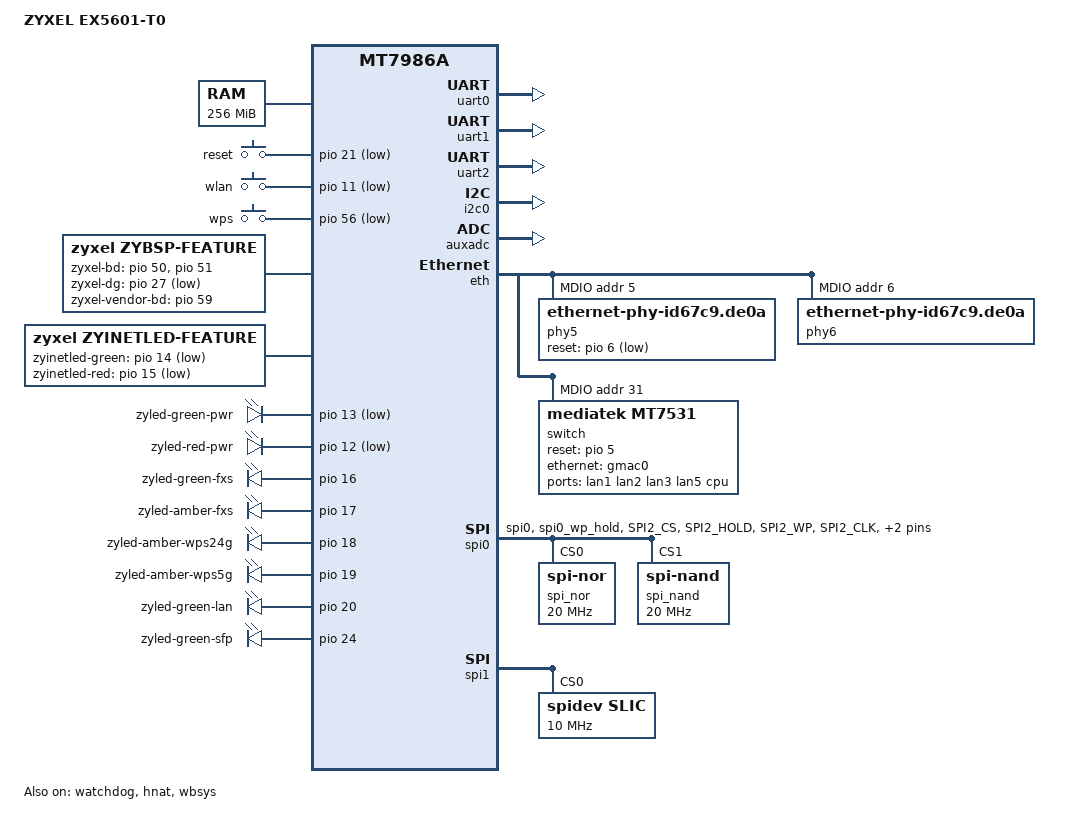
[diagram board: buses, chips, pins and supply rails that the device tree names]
/dts-v1/;
#include "mt7986a.dtsi"
#include "mt7986a-pinctrl.dtsi"
#include "mt7986-spim-nand-512M-256kB-partition.dtsi"
#include <dt-bindings/input/input.h>
#include <dt-bindings/gpio/gpio.h>
/ {
	model = "ZYXEL EX5601-T0";
	compatible = "mediatek,mt7986a-2500wan-spim-snand-ex5601-t0";
	chosen {
		bootargs = "console=ttyS0,115200n1 loglevel=8  \
				earlycon=uart8250,mmio32,0x11002000";
	};

	memory {
		reg = <0 0x40000000 0 0x10000000>;
	};

	sound_si3218x {
		compatible = "mediatek,mt79xx-si3218x-machine";
		mediatek,platform = <&afe>;
		/* mediatek,ext-codec = <&proslic_spi>; */
		mediatek,ext-codec = <&dummy_codec>;
		status = "okay";
	};

	dummy_codec:dummy_codec {
			compatible = "d2,slic-dummy-codec";
	};

	gpio-keys {
		compatible = "gpio-keys";
		poll-interval = <20>;

		reset-button {
			label = "reset";
			gpios = <&pio 21 GPIO_ACTIVE_LOW>;
			linux,code = <KEY_RESTART>;
		};
		wlan-button {
			label = "wlan";
			gpios = <&pio 11 GPIO_ACTIVE_LOW>;
			linux,code = <KEY_WLAN>;
		};
		wps-button {
			label = "wps";
			gpios = <&pio 56 GPIO_ACTIVE_LOW>;
			linux,code = <KEY_WPS_BUTTON>;
		};
	};

	zybsp {
		compatible = "zyxel,zybsp-feature";
		zyxel-bd-gpios = <&pio 50 GPIO_ACTIVE_HIGH>,<&pio 51 GPIO_ACTIVE_HIGH>;
		zyxel-dg-gpios = <&pio 27 GPIO_ACTIVE_LOW>;
		zyxel-vendor-bd-gpios = <&pio 59 GPIO_ACTIVE_HIGH>;
	};

	zyinetled {
		compatible = "zyxel,zyinetled-feature";
		zyinetled-green-gpios = <&pio 14 GPIO_ACTIVE_LOW>;
		zyinetled-red-gpios = <&pio 15 GPIO_ACTIVE_LOW>;
	};

	zyleds {
		compatible = "gpio-leds";

		led_green_pwr {
			label = "zyled-green-pwr";
			gpios = <&pio 13 GPIO_ACTIVE_LOW>;
			linux,default-trigger = "timer"; /* Default blinking */
			led-pattern = <125 125>; /* Fast blink is 4 HZ */
		};

		led_red_pwr {
			label = "zyled-red-pwr";
			gpios = <&pio 12 GPIO_ACTIVE_LOW>;
			default-state = "off";
		};

		led_green_fxs {
			label = "zyled-green-fxs";
			gpios = <&pio 16 GPIO_ACTIVE_HIGH>;
			default-state = "off";
		};

		led_amber_fxs {
			label = "zyled-amber-fxs";
			gpios = <&pio 17 GPIO_ACTIVE_HIGH>;
			default-state = "off";
		};

		led_amber_wps24g {
			label = "zyled-amber-wps24g";
			gpios = <&pio 18 GPIO_ACTIVE_HIGH>;
			default-state = "off";
		};

		led_amber_wps5g {
			label = "zyled-amber-wps5g";
			gpios = <&pio 19 GPIO_ACTIVE_HIGH>;
			default-state = "off";
		};

		led_green_lan {
			label = "zyled-green-lan";
			gpios = <&pio 20 GPIO_ACTIVE_HIGH>;
			default-state = "off";
		};

		led_green_sfp {
			label = "zyled-green-sfp";
			gpios = <&pio 24 GPIO_ACTIVE_HIGH>;
			default-state = "off";
		};

	};

};

&pwm {
	pinctrl-names = "default";
	pinctrl-0 = <&pwm0_pin &pwm1_pin_g1>;
	status = "disabled";
};

&uart0 {
	status = "okay";
};

&uart1 {
	pinctrl-names = "default";
	pinctrl-0 = <&uart1_pins>;
	status = "okay";
};

&uart2 {
	pinctrl-names = "default";
	pinctrl-0 = <&uart2_pins>;
	status = "okay";
};

&i2c0 {
	pinctrl-names = "default";
	pinctrl-0 = <&i2c_pins>;
	status = "okay";
};

&auxadc {
	status = "okay";
};

&watchdog {
	status = "okay";
};

&eth {
	status = "okay";

	gmac0: mac@0 {
		compatible = "mediatek,eth-mac";
		reg = <0>;
		phy-mode = "2500base-x";

		fixed-link {
			speed = <2500>;
			full-duplex;
			pause;
		};
	};

	gmac1: mac@1 {
		compatible = "mediatek,eth-mac";
		reg = <1>;
		phy-mode = "2500base-x";

		fixed-link {
			speed = <2500>;
			full-duplex;
			pause;
		};
	};

	mdio: mdio-bus {
		#address-cells = <1>;
		#size-cells = <0>;

		phy5: phy@5 {
			compatible = "ethernet-phy-id67c9.de0a";
			reg = <5>;
			reset-gpios = <&pio 6 1>;
			reset-assert-us = <50000>;
			reset-deassert-us = <20000>;
			phy-mode = "2500base-x";
			maxlinear,led-reg = <1008 0 0 0>; /* enable led0 for all link/act, and disable led1~3 */
			ifname = "lan5";
		};

		phy6: phy@6 {
			compatible = "ethernet-phy-id67c9.de0a";
			reg = <6>;
			phy-mode = "2500base-x";
			maxlinear,led-reg = <240 0 0 0>; /* enable led0 and no pulsing with TX, RX, and disable led1~3 */
			ifname = "eth1";
		};

		switch@0 {
			compatible = "mediatek,mt7531";
			reg = <31>;
			reset-gpios = <&pio 5 0>;

			ports {
				#address-cells = <1>;
				#size-cells = <0>;

				port@1 {
					reg = <1>;
					label = "lan1";
				};

				port@2 {
					reg = <2>;
					label = "lan2";
				};

				port@3 {
					reg = <3>;
					label = "lan3";
				};

				port@5 {
					reg = <5>;
					label = "lan5";
					phy-mode = "2500base-x";

					fixed-link {
						speed = <2500>;
						full-duplex;
						pause;
					};
				};

				port@6 {
					reg = <6>;
					label = "cpu";
					ethernet = <&gmac0>;
					phy-mode = "2500base-x";

					fixed-link {
						speed = <2500>;
						full-duplex;
						pause;
					};
				};
			};
		};
	};
};

&xhci {
	mtk,enable-gpios = <&pio 8 1>;
	mtk,oc-gpios = <&pio 7 1>;
};

&hnat {
	mtketh-wan = "eth1";
	mtketh-lan = "lan";
	mtketh-max-gmac = <2>;
	status = "okay";
};

&spi0 {
	pinctrl-names = "default";
	pinctrl-0 = <&spi_flash_pins>;
	cs-gpios = <0>, <0>;
	status = "okay";

	spi_nor@0 {
		#address-cells = <1>;
		#size-cells = <1>;
		compatible = "jedec,spi-nor";
		reg = <0>;
		spi-max-frequency = <20000000>;
		spi-tx-buswidth = <4>;
		spi-rx-buswidth = <4>;
	};

	spi_nand: spi_nand@1 {
		#address-cells = <1>;
		#size-cells = <1>;
		compatible = "spi-nand";
		reg = <1>;
		spi-max-frequency = <20000000>;
		spi-tx-buswidth = <4>;
		spi-rx-buswidth = <4>;
	};
};

&spi1 {
	pinctrl-names = "default";
	pinctrl-0 = <&spic_pins_g2>;
	status = "okay";

	/*
	 * proslic_spi: proslic_spi@0 {
	 *	compatible = "silabs,proslic_spi";
	 *	reg = <0>;
	 *	spi-max-frequency = <10000000>;
	 *	spi-cpha = <1>;
	 *	spi-cpol = <1>;
	 *	channel_count = <1>;
	 *	debug_level = <4>;       // 1 = TRC, 2 = DBG, 4 = ERR //
	 *	reset_gpio = <&pio 25 0>;
	 *	ig,enable-spi = <1>;     // 1: Enable, 0: Disable //
	 * };
	 */

    spidev@0 {
        compatible = "spidev,slic";
        spi-max-frequency = <10000000>;
        reg = <0>;

	};

};

&pcie0 {
	pinctrl-names = "default";
	pinctrl-0 = <&pcie0_pins>;
	status = "disabled";
};

&wbsys {
	mediatek,mtd-eeprom = <&factory 0x0000>;
	status = "okay";
	pinctrl-names = "default", "dbdc";
	pinctrl-0 = <&wf_2g_5g_pins>;
	pinctrl-1 = <&wf_dbdc_pins>;
};

&pio {
	spi_flash_pins: spi-flash-pins-33-to-38 {
		mux {
			function = "flash";
			groups = "spi0", "spi0_wp_hold";
		};
		conf-pu {
			pins = "SPI2_CS", "SPI2_HOLD", "SPI2_WP";
			drive-strength = <MTK_DRIVE_8mA>;
			mediatek,pull-up-adv = <0>;	/* bias-disable */
		};
		conf-pd {
			pins = "SPI2_CLK", "SPI2_MOSI", "SPI2_MISO";
			drive-strength = <MTK_DRIVE_8mA>;
			mediatek,pull-down-adv = <0>;	/* bias-disable */
		};
	};

	wf_2g_5g_pins: wf_2g_5g-pins {
		mux {
			function = "wifi";
			groups = "wf_2g", "wf_5g";
		};
		conf {
			pins = "WF0_HB1", "WF0_HB2", "WF0_HB3", "WF0_HB4",
			       "WF0_HB0", "WF0_HB0_B", "WF0_HB5", "WF0_HB6",
			       "WF0_HB7", "WF0_HB8", "WF0_HB9", "WF0_HB10",
			       "WF0_TOP_CLK", "WF0_TOP_DATA", "WF1_HB1",
			       "WF1_HB2", "WF1_HB3", "WF1_HB4", "WF1_HB0",
			       "WF1_HB5", "WF1_HB6", "WF1_HB7", "WF1_HB8",
			       "WF1_TOP_CLK", "WF1_TOP_DATA";
			drive-strength = <MTK_DRIVE_4mA>;
		};
	};

	wf_dbdc_pins: wf_dbdc-pins {
		mux {
			function = "wifi";
			groups = "wf_dbdc";
		};
		conf {
			pins = "WF0_HB1", "WF0_HB2", "WF0_HB3", "WF0_HB4",
			       "WF0_HB0", "WF0_HB0_B", "WF0_HB5", "WF0_HB6",
			       "WF0_HB7", "WF0_HB8", "WF0_HB9", "WF0_HB10",
			       "WF0_TOP_CLK", "WF0_TOP_DATA", "WF1_HB1",
			       "WF1_HB2", "WF1_HB3", "WF1_HB4", "WF1_HB0",
			       "WF1_HB5", "WF1_HB6", "WF1_HB7", "WF1_HB8",
			       "WF1_TOP_CLK", "WF1_TOP_DATA";
			drive-strength = <MTK_DRIVE_4mA>;
		};
	};
};
